# f29h85x_ssu_cpu2_cfg_regs register map
Vendor: Texas Instruments
Peripheral module from a debugger description file (folder C29).
Registers are 32-bit, read-write, no defined reset value unless marked. A register's access mark holds for its fields unless they carry their own. Offsets are as the file gives them; lines under a group give offsets from that group; [hi:lo] are bit positions; {n}, {i} and the like mark numbered series; 'fields as' and 'values as' point back to an identical list; <NAME> marks a mode.

## SSU_CPU2_CFG_REGS — SSU CPU2 CFG Registers
0x00 RST_VECT — CPU Reset Vector
  [31:0] ADDR — Reset Vector Address
0x04 RST_LINK — CPU Reset LINK
  [3:0] LINK — Reset LINK Value
0x08 CPU_RST_CTRL — CPU Reset Control
  [7:0] SW_SYSRSN — System CPU Reset
0x10 DEF_NMI_VECT — Default CPU NMI Vector
  [31:0] ADDR — Default NMI Vector Address
0x14 DEF_NMI_LINK — Default CPU NMI LINK
  [3:0] LINK — Default NMI LINK Value
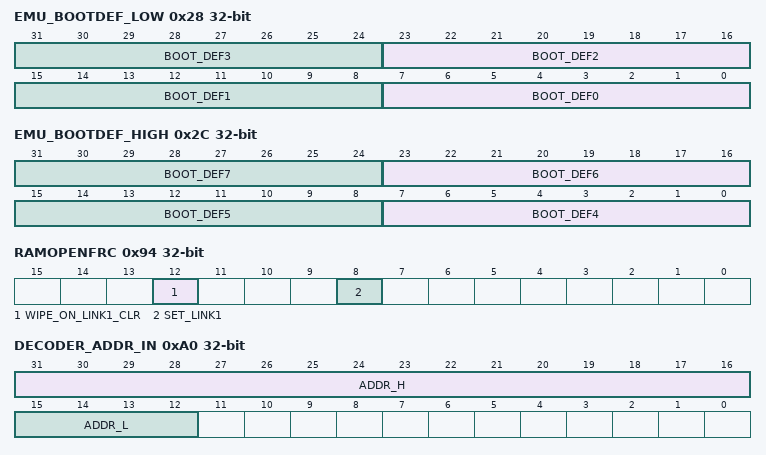
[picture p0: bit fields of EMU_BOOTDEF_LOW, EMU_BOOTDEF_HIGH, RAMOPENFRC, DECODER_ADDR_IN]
0x28 EMU_BOOTDEF_LOW — User Emulation Boot Definition Low Register
  [8n+7:8n] BOOT_DEF{n} (n=0..3) — Boot Definitions {n}
0x2C EMU_BOOTDEF_HIGH — User Emulation Boot Definition High Register
  [8n-25:8n-32] BOOT_DEF{n} (n=4..7) — Boot Definitions {n}
{0x30+4i} LINK{i}_CFG (i=3..15) — LINK{i} Configuration
  [2:0] STACK — STACK Association
{0x70+4i} STACK{i}_CFG (i=3..7) — STACK{i} Configuration
  [1:0] ZONE — ZONE Association
0x90 RAMOPENSTAT ro — RAMOPEN Feature Status Register
  [1] LINK1_RAMOPENS — LINK1 RAM Open Status Bit
0x94 RAMOPENFRC — RAMOPEN Feature Force Register
  [12] WIPE_ON_LINK1_CLR — Wipe LINK1 RAM on Clear Request
  [8] SET_LINK1 — Set LINK1 RAM Open Request
0x98 RAMOPENCLR — RAMOPEN Feature Clear Register
  [1] CLEAR_LINK1 — Clear LINK1 RAM Open Request
0xA0 DECODER_ADDR_IN — SW ZONE Decoder Address Input
  [31:16] ADDR_H — Address Bits 31:16
  [15:12] ADDR_L — Address Bits 15:12
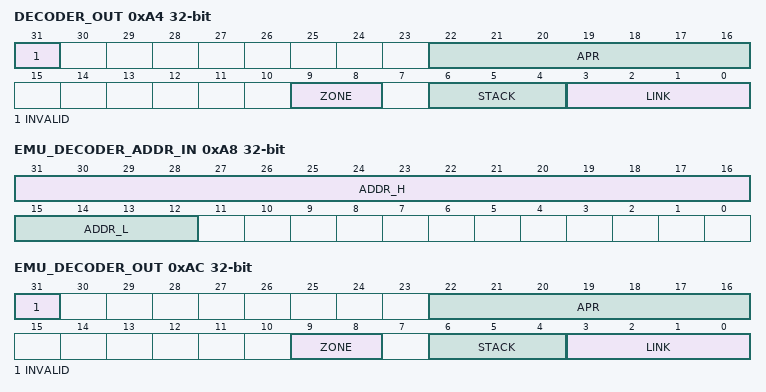
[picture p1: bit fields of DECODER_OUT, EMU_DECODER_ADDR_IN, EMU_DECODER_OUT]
0xA4 DECODER_OUT ro — SW ZONE Decoder Output
  [31] INVALID — Decoder Output Invalid
  [22:16] APR — Access Protection Region
  [9:8] ZONE — Decoded ZONE
  [6:4] STACK — Decoded STACK
  [3:0] LINK — Decoded LINK
0xA8 EMU_DECODER_ADDR_IN — SW ZONE Decoder Address Input
  fields as DECODER_ADDR_IN
0xAC EMU_DECODER_OUT ro — SW ZONE Decoder Output
  fields as DECODER_OUT
